# StarFive VisionFive 2 v1.3b register map
File version: 0.1
Registers are 32-bit, read-write, no defined reset value unless marked. A register's access mark holds for its fields unless they carry their own. Offsets are from the block's base; [hi:lo] are bit positions.

## starfive_jh7110_sys_pinctrl_0 (part 2 of 3) — From starfive,jh7110-sys-pinctrl, peripheral generator
Base 0x13040000
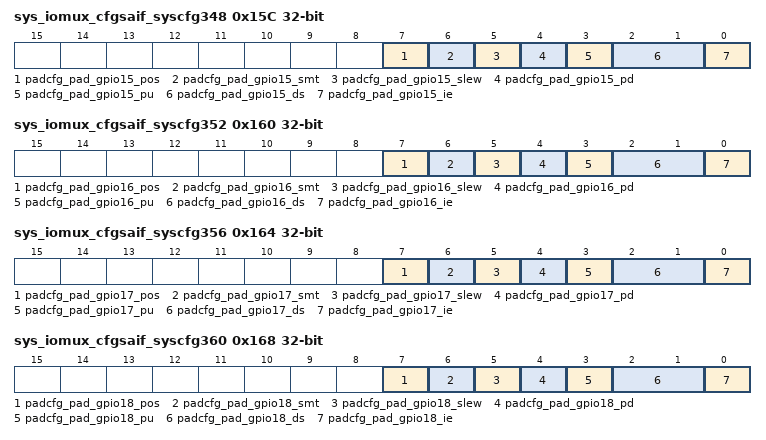
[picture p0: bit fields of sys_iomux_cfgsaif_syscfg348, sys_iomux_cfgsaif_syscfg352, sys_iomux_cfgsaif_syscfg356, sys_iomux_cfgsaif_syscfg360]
0x15C sys_iomux_cfgsaif_syscfg348
  [7] padcfg_pad_gpio15_pos — Power-on-Start (POS) enabler - 1: Enable active pull down for loss of core power, 0: Active pull-down capability disabled
  [6] padcfg_pad_gpio15_smt — Active high Schmitt (SMT) trigger selector - 0: No hysteresis, 1: Schmitt trigger ebabled
  [5] padcfg_pad_gpio15_slew — Slew Rate Control - 0: Slow (Half frequency), 1: Fast
  [4] padcfg_pad_gpio15_pd — Pull-Down (PD) settings - 1: Yes, 0: No
  [3] padcfg_pad_gpio15_pu — Pull-Up (PU) settings - 1: Yes, 0: No
  [2:1] padcfg_pad_gpio15_ds — Output Drive Strength (DS) - 00: The rated drive strength is 2 mA, 01: The rated drive strength is 4 mA, 10: The rated drive strength is 8 mA, 11: The rated drive strength is 12 mA
  [0] padcfg_pad_gpio15_ie — Input Enable (IE) Controller - 1: Enable the receiver, 0: Disable the receiver
0x160 sys_iomux_cfgsaif_syscfg352
  [7] padcfg_pad_gpio16_pos — Power-on-Start (POS) enabler - 1: Enable active pull down for loss of core power, 0: Active pull-down capability disabled
  [6] padcfg_pad_gpio16_smt — Active high Schmitt (SMT) trigger selector - 0: No hysteresis, 1: Schmitt trigger ebabled
  [5] padcfg_pad_gpio16_slew — Slew Rate Control - 0: Slow (Half frequency), 1: Fast
  [4] padcfg_pad_gpio16_pd — Pull-Down (PD) settings - 1: Yes, 0: No
  [3] padcfg_pad_gpio16_pu — Pull-Up (PU) settings - 1: Yes, 0: No
  [2:1] padcfg_pad_gpio16_ds — Output Drive Strength (DS) - 00: The rated drive strength is 2 mA, 01: The rated drive strength is 4 mA, 10: The rated drive strength is 8 mA, 11: The rated drive strength is 12 mA
  [0] padcfg_pad_gpio16_ie — Input Enable (IE) Controller - 1: Enable the receiver, 0: Disable the receiver
0x164 sys_iomux_cfgsaif_syscfg356
  [7] padcfg_pad_gpio17_pos — Power-on-Start (POS) enabler - 1: Enable active pull down for loss of core power, 0: Active pull-down capability disabled
  [6] padcfg_pad_gpio17_smt — Active high Schmitt (SMT) trigger selector - 0: No hysteresis, 1: Schmitt trigger ebabled
  [5] padcfg_pad_gpio17_slew — Slew Rate Control - 0: Slow (Half frequency), 1: Fast
  [4] padcfg_pad_gpio17_pd — Pull-Down (PD) settings - 1: Yes, 0: No
  [3] padcfg_pad_gpio17_pu — Pull-Up (PU) settings - 1: Yes, 0: No
  [2:1] padcfg_pad_gpio17_ds — Output Drive Strength (DS) - 00: The rated drive strength is 2 mA, 01: The rated drive strength is 4 mA, 10: The rated drive strength is 8 mA, 11: The rated drive strength is 12 mA
  [0] padcfg_pad_gpio17_ie — Input Enable (IE) Controller - 1: Enable the receiver, 0: Disable the receiver
0x168 sys_iomux_cfgsaif_syscfg360
  [7] padcfg_pad_gpio18_pos — Power-on-Start (POS) enabler - 1: Enable active pull down for loss of core power, 0: Active pull-down capability disabled
  [6] padcfg_pad_gpio18_smt — Active high Schmitt (SMT) trigger selector - 0: No hysteresis, 1: Schmitt trigger ebabled
  [5] padcfg_pad_gpio18_slew — Slew Rate Control - 0: Slow (Half frequency), 1: Fast
  [4] padcfg_pad_gpio18_pd — Pull-Down (PD) settings - 1: Yes, 0: No
  [3] padcfg_pad_gpio18_pu — Pull-Up (PU) settings - 1: Yes, 0: No
  [2:1] padcfg_pad_gpio18_ds — Output Drive Strength (DS) - 00: The rated drive strength is 2 mA, 01: The rated drive strength is 4 mA, 10: The rated drive strength is 8 mA, 11: The rated drive strength is 12 mA
  [0] padcfg_pad_gpio18_ie — Input Enable (IE) Controller - 1: Enable the receiver, 0: Disable the receiver
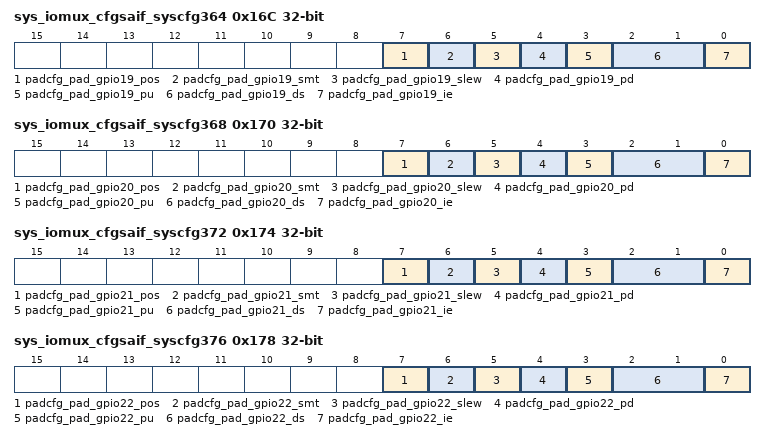
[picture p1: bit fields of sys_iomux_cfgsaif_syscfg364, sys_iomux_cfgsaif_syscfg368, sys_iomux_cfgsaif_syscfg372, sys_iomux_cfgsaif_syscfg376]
0x16C sys_iomux_cfgsaif_syscfg364
  [7] padcfg_pad_gpio19_pos — Power-on-Start (POS) enabler - 1: Enable active pull down for loss of core power, 0: Active pull-down capability disabled
  [6] padcfg_pad_gpio19_smt — Active high Schmitt (SMT) trigger selector - 0: No hysteresis, 1: Schmitt trigger ebabled
  [5] padcfg_pad_gpio19_slew — Slew Rate Control - 0: Slow (Half frequency), 1: Fast
  [4] padcfg_pad_gpio19_pd — Pull-Down (PD) settings - 1: Yes, 0: No
  [3] padcfg_pad_gpio19_pu — Pull-Up (PU) settings - 1: Yes, 0: No
  [2:1] padcfg_pad_gpio19_ds — Output Drive Strength (DS) - 00: The rated drive strength is 2 mA, 01: The rated drive strength is 4 mA, 10: The rated drive strength is 8 mA, 11: The rated drive strength is 12 mA
  [0] padcfg_pad_gpio19_ie — Input Enable (IE) Controller - 1: Enable the receiver, 0: Disable the receiver
0x170 sys_iomux_cfgsaif_syscfg368
  [7] padcfg_pad_gpio20_pos — Power-on-Start (POS) enabler - 1: Enable active pull down for loss of core power, 0: Active pull-down capability disabled
  [6] padcfg_pad_gpio20_smt — Active high Schmitt (SMT) trigger selector - 0: No hysteresis, 1: Schmitt trigger ebabled
  [5] padcfg_pad_gpio20_slew — Slew Rate Control - 0: Slow (Half frequency), 1: Fast
  [4] padcfg_pad_gpio20_pd — Pull-Down (PD) settings - 1: Yes, 0: No
  [3] padcfg_pad_gpio20_pu — Pull-Up (PU) settings - 1: Yes, 0: No
  [2:1] padcfg_pad_gpio20_ds — Output Drive Strength (DS) - 00: The rated drive strength is 2 mA, 01: The rated drive strength is 4 mA, 10: The rated drive strength is 8 mA, 11: The rated drive strength is 12 mA
  [0] padcfg_pad_gpio20_ie — Input Enable (IE) Controller - 1: Enable the receiver, 0: Disable the receiver
0x174 sys_iomux_cfgsaif_syscfg372
  [7] padcfg_pad_gpio21_pos — Power-on-Start (POS) enabler - 1: Enable active pull down for loss of core power, 0: Active pull-down capability disabled
  [6] padcfg_pad_gpio21_smt — Active high Schmitt (SMT) trigger selector - 0: No hysteresis, 1: Schmitt trigger ebabled
  [5] padcfg_pad_gpio21_slew — Slew Rate Control - 0: Slow (Half frequency), 1: Fast
  [4] padcfg_pad_gpio21_pd — Pull-Down (PD) settings - 1: Yes, 0: No
  [3] padcfg_pad_gpio21_pu — Pull-Up (PU) settings - 1: Yes, 0: No
  [2:1] padcfg_pad_gpio21_ds — Output Drive Strength (DS) - 00: The rated drive strength is 2 mA, 01: The rated drive strength is 4 mA, 10: The rated drive strength is 8 mA, 11: The rated drive strength is 12 mA
  [0] padcfg_pad_gpio21_ie — Input Enable (IE) Controller - 1: Enable the receiver, 0: Disable the receiver
0x178 sys_iomux_cfgsaif_syscfg376
  [7] padcfg_pad_gpio22_pos — Power-on-Start (POS) enabler - 1: Enable active pull down for loss of core power, 0: Active pull-down capability disabled
  [6] padcfg_pad_gpio22_smt — Active high Schmitt (SMT) trigger selector - 0: No hysteresis, 1: Schmitt trigger ebabled
  [5] padcfg_pad_gpio22_slew — Slew Rate Control - 0: Slow (Half frequency), 1: Fast
  [4] padcfg_pad_gpio22_pd — Pull-Down (PD) settings - 1: Yes, 0: No
  [3] padcfg_pad_gpio22_pu — Pull-Up (PU) settings - 1: Yes, 0: No
  [2:1] padcfg_pad_gpio22_ds — Output Drive Strength (DS) - 00: The rated drive strength is 2 mA, 01: The rated drive strength is 4 mA, 10: The rated drive strength is 8 mA, 11: The rated drive strength is 12 mA
  [0] padcfg_pad_gpio22_ie — Input Enable (IE) Controller - 1: Enable the receiver, 0: Disable the receiver
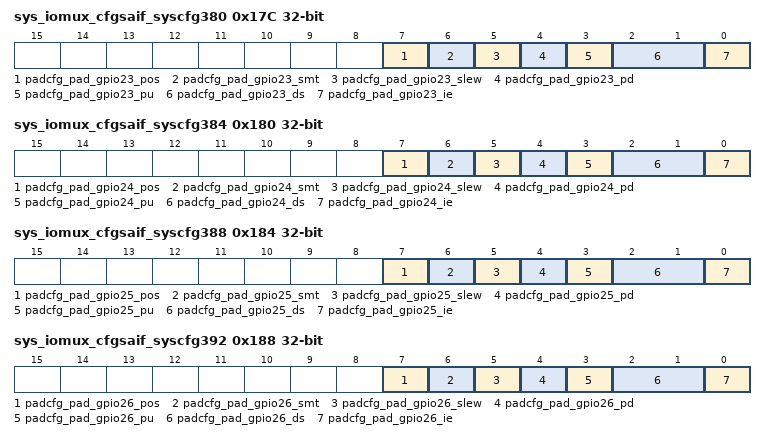
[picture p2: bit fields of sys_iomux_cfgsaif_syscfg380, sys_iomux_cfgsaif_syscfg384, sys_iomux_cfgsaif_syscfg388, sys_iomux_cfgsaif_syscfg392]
0x17C sys_iomux_cfgsaif_syscfg380
  [7] padcfg_pad_gpio23_pos — Power-on-Start (POS) enabler - 1: Enable active pull down for loss of core power, 0: Active pull-down capability disabled
  [6] padcfg_pad_gpio23_smt — Active high Schmitt (SMT) trigger selector - 0: No hysteresis, 1: Schmitt trigger ebabled
  [5] padcfg_pad_gpio23_slew — Slew Rate Control - 0: Slow (Half frequency), 1: Fast
  [4] padcfg_pad_gpio23_pd — Pull-Down (PD) settings - 1: Yes, 0: No
  [3] padcfg_pad_gpio23_pu — Pull-Up (PU) settings - 1: Yes, 0: No
  [2:1] padcfg_pad_gpio23_ds — Output Drive Strength (DS) - 00: The rated drive strength is 2 mA, 01: The rated drive strength is 4 mA, 10: The rated drive strength is 8 mA, 11: The rated drive strength is 12 mA
  [0] padcfg_pad_gpio23_ie — Input Enable (IE) Controller - 1: Enable the receiver, 0: Disable the receiver
0x180 sys_iomux_cfgsaif_syscfg384
  [7] padcfg_pad_gpio24_pos — Power-on-Start (POS) enabler - 1: Enable active pull down for loss of core power, 0: Active pull-down capability disabled
  [6] padcfg_pad_gpio24_smt — Active high Schmitt (SMT) trigger selector - 0: No hysteresis, 1: Schmitt trigger ebabled
  [5] padcfg_pad_gpio24_slew — Slew Rate Control - 0: Slow (Half frequency), 1: Fast
  [4] padcfg_pad_gpio24_pd — Pull-Down (PD) settings - 1: Yes, 0: No
  [3] padcfg_pad_gpio24_pu — Pull-Up (PU) settings - 1: Yes, 0: No
  [2:1] padcfg_pad_gpio24_ds — Output Drive Strength (DS) - 00: The rated drive strength is 2 mA, 01: The rated drive strength is 4 mA, 10: The rated drive strength is 8 mA, 11: The rated drive strength is 12 mA
  [0] padcfg_pad_gpio24_ie — Input Enable (IE) Controller - 1: Enable the receiver, 0: Disable the receiver
0x184 sys_iomux_cfgsaif_syscfg388
  [7] padcfg_pad_gpio25_pos — Power-on-Start (POS) enabler - 1: Enable active pull down for loss of core power, 0: Active pull-down capability disabled
  [6] padcfg_pad_gpio25_smt — Active high Schmitt (SMT) trigger selector - 0: No hysteresis, 1: Schmitt trigger ebabled
  [5] padcfg_pad_gpio25_slew — Slew Rate Control - 0: Slow (Half frequency), 1: Fast
  [4] padcfg_pad_gpio25_pd — Pull-Down (PD) settings - 1: Yes, 0: No
  [3] padcfg_pad_gpio25_pu — Pull-Up (PU) settings - 1: Yes, 0: No
  [2:1] padcfg_pad_gpio25_ds — Output Drive Strength (DS) - 00: The rated drive strength is 2 mA, 01: The rated drive strength is 4 mA, 10: The rated drive strength is 8 mA, 11: The rated drive strength is 12 mA
  [0] padcfg_pad_gpio25_ie — Input Enable (IE) Controller - 1: Enable the receiver, 0: Disable the receiver
0x188 sys_iomux_cfgsaif_syscfg392
  [7] padcfg_pad_gpio26_pos — Power-on-Start (POS) enabler - 1: Enable active pull down for loss of core power, 0: Active pull-down capability disabled
  [6] padcfg_pad_gpio26_smt — Active high Schmitt (SMT) trigger selector - 0: No hysteresis, 1: Schmitt trigger ebabled
  [5] padcfg_pad_gpio26_slew — Slew Rate Control - 0: Slow (Half frequency), 1: Fast
  [4] padcfg_pad_gpio26_pd — Pull-Down (PD) settings - 1: Yes, 0: No
  [3] padcfg_pad_gpio26_pu — Pull-Up (PU) settings - 1: Yes, 0: No
  [2:1] padcfg_pad_gpio26_ds — Output Drive Strength (DS) - 00: The rated drive strength is 2 mA, 01: The rated drive strength is 4 mA, 10: The rated drive strength is 8 mA, 11: The rated drive strength is 12 mA
  [0] padcfg_pad_gpio26_ie — Input Enable (IE) Controller - 1: Enable the receiver, 0: Disable the receiver
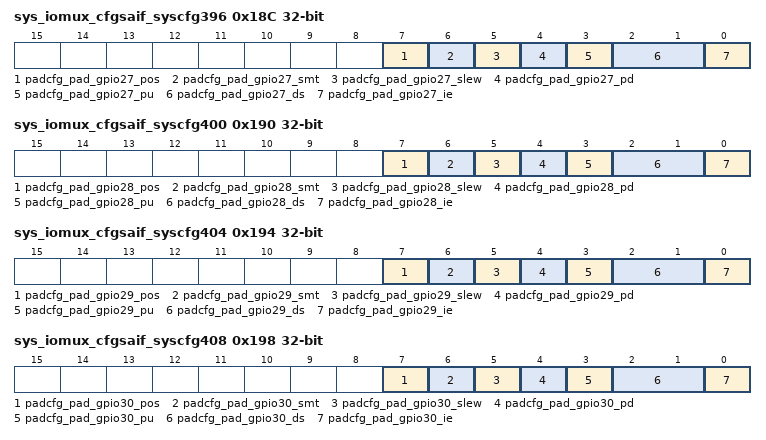
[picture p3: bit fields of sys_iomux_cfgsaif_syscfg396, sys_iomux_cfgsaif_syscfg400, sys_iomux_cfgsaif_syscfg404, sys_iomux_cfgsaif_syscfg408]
0x18C sys_iomux_cfgsaif_syscfg396
  [7] padcfg_pad_gpio27_pos — Power-on-Start (POS) enabler - 1: Enable active pull down for loss of core power, 0: Active pull-down capability disabled
  [6] padcfg_pad_gpio27_smt — Active high Schmitt (SMT) trigger selector - 0: No hysteresis, 1: Schmitt trigger ebabled
  [5] padcfg_pad_gpio27_slew — Slew Rate Control - 0: Slow (Half frequency), 1: Fast
  [4] padcfg_pad_gpio27_pd — Pull-Down (PD) settings - 1: Yes, 0: No
  [3] padcfg_pad_gpio27_pu — Pull-Up (PU) settings - 1: Yes, 0: No
  [2:1] padcfg_pad_gpio27_ds — Output Drive Strength (DS) - 00: The rated drive strength is 2 mA, 01: The rated drive strength is 4 mA, 10: The rated drive strength is 8 mA, 11: The rated drive strength is 12 mA
  [0] padcfg_pad_gpio27_ie — Input Enable (IE) Controller - 1: Enable the receiver, 0: Disable the receiver
0x190 sys_iomux_cfgsaif_syscfg400
  [7] padcfg_pad_gpio28_pos — Power-on-Start (POS) enabler - 1: Enable active pull down for loss of core power, 0: Active pull-down capability disabled
  [6] padcfg_pad_gpio28_smt — Active high Schmitt (SMT) trigger selector - 0: No hysteresis, 1: Schmitt trigger ebabled
  [5] padcfg_pad_gpio28_slew — Slew Rate Control - 0: Slow (Half frequency), 1: Fast
  [4] padcfg_pad_gpio28_pd — Pull-Down (PD) settings - 1: Yes, 0: No
  [3] padcfg_pad_gpio28_pu — Pull-Up (PU) settings - 1: Yes, 0: No
  [2:1] padcfg_pad_gpio28_ds — Output Drive Strength (DS) - 00: The rated drive strength is 2 mA, 01: The rated drive strength is 4 mA, 10: The rated drive strength is 8 mA, 11: The rated drive strength is 12 mA
  [0] padcfg_pad_gpio28_ie — Input Enable (IE) Controller - 1: Enable the receiver, 0: Disable the receiver
0x194 sys_iomux_cfgsaif_syscfg404
  [7] padcfg_pad_gpio29_pos — Power-on-Start (POS) enabler - 1: Enable active pull down for loss of core power, 0: Active pull-down capability disabled
  [6] padcfg_pad_gpio29_smt — Active high Schmitt (SMT) trigger selector - 0: No hysteresis, 1: Schmitt trigger ebabled
  [5] padcfg_pad_gpio29_slew — Slew Rate Control - 0: Slow (Half frequency), 1: Fast
  [4] padcfg_pad_gpio29_pd — Pull-Down (PD) settings - 1: Yes, 0: No
  [3] padcfg_pad_gpio29_pu — Pull-Up (PU) settings - 1: Yes, 0: No
  [2:1] padcfg_pad_gpio29_ds — Output Drive Strength (DS) - 00: The rated drive strength is 2 mA, 01: The rated drive strength is 4 mA, 10: The rated drive strength is 8 mA, 11: The rated drive strength is 12 mA
  [0] padcfg_pad_gpio29_ie — Input Enable (IE) Controller - 1: Enable the receiver, 0: Disable the receiver
0x198 sys_iomux_cfgsaif_syscfg408
  [7] padcfg_pad_gpio30_pos — Power-on-Start (POS) enabler - 1: Enable active pull down for loss of core power, 0: Active pull-down capability disabled
  [6] padcfg_pad_gpio30_smt — Active high Schmitt (SMT) trigger selector - 0: No hysteresis, 1: Schmitt trigger ebabled
  [5] padcfg_pad_gpio30_slew — Slew Rate Control - 0: Slow (Half frequency), 1: Fast
  [4] padcfg_pad_gpio30_pd — Pull-Down (PD) settings - 1: Yes, 0: No
  [3] padcfg_pad_gpio30_pu — Pull-Up (PU) settings - 1: Yes, 0: No
  [2:1] padcfg_pad_gpio30_ds — Output Drive Strength (DS) - 00: The rated drive strength is 2 mA, 01: The rated drive strength is 4 mA, 10: The rated drive strength is 8 mA, 11: The rated drive strength is 12 mA
  [0] padcfg_pad_gpio30_ie — Input Enable (IE) Controller - 1: Enable the receiver, 0: Disable the receiver
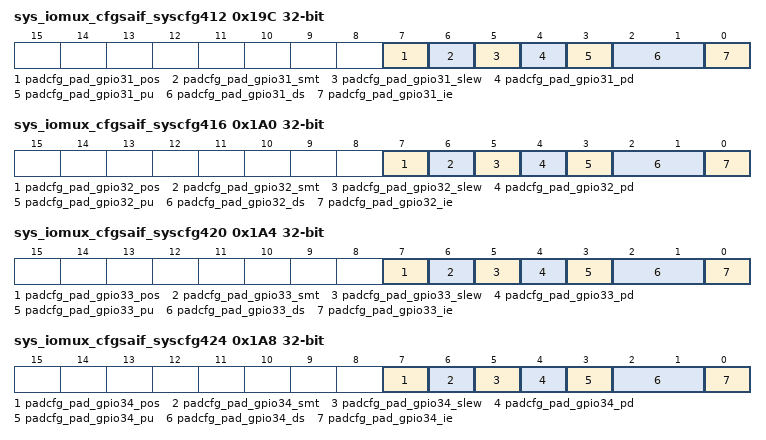
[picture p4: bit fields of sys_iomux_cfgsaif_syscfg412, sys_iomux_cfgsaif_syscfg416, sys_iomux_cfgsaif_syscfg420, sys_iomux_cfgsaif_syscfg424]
0x19C sys_iomux_cfgsaif_syscfg412
  [7] padcfg_pad_gpio31_pos — Power-on-Start (POS) enabler - 1: Enable active pull down for loss of core power, 0: Active pull-down capability disabled
  [6] padcfg_pad_gpio31_smt — Active high Schmitt (SMT) trigger selector - 0: No hysteresis, 1: Schmitt trigger ebabled
  [5] padcfg_pad_gpio31_slew — Slew Rate Control - 0: Slow (Half frequency), 1: Fast
  [4] padcfg_pad_gpio31_pd — Pull-Down (PD) settings - 1: Yes, 0: No
  [3] padcfg_pad_gpio31_pu — Pull-Up (PU) settings - 1: Yes, 0: No
  [2:1] padcfg_pad_gpio31_ds — Output Drive Strength (DS) - 00: The rated drive strength is 2 mA, 01: The rated drive strength is 4 mA, 10: The rated drive strength is 8 mA, 11: The rated drive strength is 12 mA
  [0] padcfg_pad_gpio31_ie — Input Enable (IE) Controller - 1: Enable the receiver, 0: Disable the receiver
0x1A0 sys_iomux_cfgsaif_syscfg416
  [7] padcfg_pad_gpio32_pos — Power-on-Start (POS) enabler - 1: Enable active pull down for loss of core power, 0: Active pull-down capability disabled
  [6] padcfg_pad_gpio32_smt — Active high Schmitt (SMT) trigger selector - 0: No hysteresis, 1: Schmitt trigger ebabled
  [5] padcfg_pad_gpio32_slew — Slew Rate Control - 0: Slow (Half frequency), 1: Fast
  [4] padcfg_pad_gpio32_pd — Pull-Down (PD) settings - 1: Yes, 0: No
  [3] padcfg_pad_gpio32_pu — Pull-Up (PU) settings - 1: Yes, 0: No
  [2:1] padcfg_pad_gpio32_ds — Output Drive Strength (DS) - 00: The rated drive strength is 2 mA, 01: The rated drive strength is 4 mA, 10: The rated drive strength is 8 mA, 11: The rated drive strength is 12 mA
  [0] padcfg_pad_gpio32_ie — Input Enable (IE) Controller - 1: Enable the receiver, 0: Disable the receiver
0x1A4 sys_iomux_cfgsaif_syscfg420
  [7] padcfg_pad_gpio33_pos — Power-on-Start (POS) enabler - 1: Enable active pull down for loss of core power, 0: Active pull-down capability disabled
  [6] padcfg_pad_gpio33_smt — Active high Schmitt (SMT) trigger selector - 0: No hysteresis, 1: Schmitt trigger ebabled
  [5] padcfg_pad_gpio33_slew — Slew Rate Control - 0: Slow (Half frequency), 1: Fast
  [4] padcfg_pad_gpio33_pd — Pull-Down (PD) settings - 1: Yes, 0: No
  [3] padcfg_pad_gpio33_pu — Pull-Up (PU) settings - 1: Yes, 0: No
  [2:1] padcfg_pad_gpio33_ds — Output Drive Strength (DS) - 00: The rated drive strength is 2 mA, 01: The rated drive strength is 4 mA, 10: The rated drive strength is 8 mA, 11: The rated drive strength is 12 mA
  [0] padcfg_pad_gpio33_ie — Input Enable (IE) Controller - 1: Enable the receiver, 0: Disable the receiver
0x1A8 sys_iomux_cfgsaif_syscfg424
  [7] padcfg_pad_gpio34_pos — Power-on-Start (POS) enabler - 1: Enable active pull down for loss of core power, 0: Active pull-down capability disabled
  [6] padcfg_pad_gpio34_smt — Active high Schmitt (SMT) trigger selector - 0: No hysteresis, 1: Schmitt trigger ebabled
  [5] padcfg_pad_gpio34_slew — Slew Rate Control - 0: Slow (Half frequency), 1: Fast
  [4] padcfg_pad_gpio34_pd — Pull-Down (PD) settings - 1: Yes, 0: No
  [3] padcfg_pad_gpio34_pu — Pull-Up (PU) settings - 1: Yes, 0: No
  [2:1] padcfg_pad_gpio34_ds — Output Drive Strength (DS) - 00: The rated drive strength is 2 mA, 01: The rated drive strength is 4 mA, 10: The rated drive strength is 8 mA, 11: The rated drive strength is 12 mA
  [0] padcfg_pad_gpio34_ie — Input Enable (IE) Controller - 1: Enable the receiver, 0: Disable the receiver
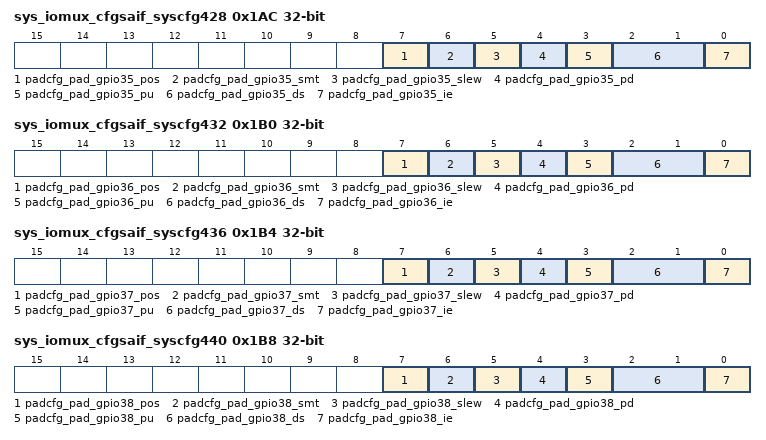
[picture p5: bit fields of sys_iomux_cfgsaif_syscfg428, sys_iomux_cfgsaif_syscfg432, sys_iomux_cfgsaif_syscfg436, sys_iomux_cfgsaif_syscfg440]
0x1AC sys_iomux_cfgsaif_syscfg428
  [7] padcfg_pad_gpio35_pos — Power-on-Start (POS) enabler - 1: Enable active pull down for loss of core power, 0: Active pull-down capability disabled
  [6] padcfg_pad_gpio35_smt — Active high Schmitt (SMT) trigger selector - 0: No hysteresis, 1: Schmitt trigger ebabled
  [5] padcfg_pad_gpio35_slew — Slew Rate Control - 0: Slow (Half frequency), 1: Fast
  [4] padcfg_pad_gpio35_pd — Pull-Down (PD) settings - 1: Yes, 0: No
  [3] padcfg_pad_gpio35_pu — Pull-Up (PU) settings - 1: Yes, 0: No
  [2:1] padcfg_pad_gpio35_ds — Output Drive Strength (DS) - 00: The rated drive strength is 2 mA, 01: The rated drive strength is 4 mA, 10: The rated drive strength is 8 mA, 11: The rated drive strength is 12 mA
  [0] padcfg_pad_gpio35_ie — Input Enable (IE) Controller - 1: Enable the receiver, 0: Disable the receiver
0x1B0 sys_iomux_cfgsaif_syscfg432
  [7] padcfg_pad_gpio36_pos — Power-on-Start (POS) enabler - 1: Enable active pull down for loss of core power, 0: Active pull-down capability disabled
  [6] padcfg_pad_gpio36_smt — Active high Schmitt (SMT) trigger selector - 0: No hysteresis, 1: Schmitt trigger ebabled
  [5] padcfg_pad_gpio36_slew — Slew Rate Control - 0: Slow (Half frequency), 1: Fast
  [4] padcfg_pad_gpio36_pd — Pull-Down (PD) settings - 1: Yes, 0: No
  [3] padcfg_pad_gpio36_pu — Pull-Up (PU) settings - 1: Yes, 0: No
  [2:1] padcfg_pad_gpio36_ds — Output Drive Strength (DS) - 00: The rated drive strength is 2 mA, 01: The rated drive strength is 4 mA, 10: The rated drive strength is 8 mA, 11: The rated drive strength is 12 mA
  [0] padcfg_pad_gpio36_ie — Input Enable (IE) Controller - 1: Enable the receiver, 0: Disable the receiver
0x1B4 sys_iomux_cfgsaif_syscfg436
  [7] padcfg_pad_gpio37_pos — Power-on-Start (POS) enabler - 1: Enable active pull down for loss of core power, 0: Active pull-down capability disabled
  [6] padcfg_pad_gpio37_smt — Active high Schmitt (SMT) trigger selector - 0: No hysteresis, 1: Schmitt trigger ebabled
  [5] padcfg_pad_gpio37_slew — Slew Rate Control - 0: Slow (Half frequency), 1: Fast
  [4] padcfg_pad_gpio37_pd — Pull-Down (PD) settings - 1: Yes, 0: No
  [3] padcfg_pad_gpio37_pu — Pull-Up (PU) settings - 1: Yes, 0: No
  [2:1] padcfg_pad_gpio37_ds — Output Drive Strength (DS) - 00: The rated drive strength is 2 mA, 01: The rated drive strength is 4 mA, 10: The rated drive strength is 8 mA, 11: The rated drive strength is 12 mA
  [0] padcfg_pad_gpio37_ie — Input Enable (IE) Controller - 1: Enable the receiver, 0: Disable the receiver
0x1B8 sys_iomux_cfgsaif_syscfg440
  [7] padcfg_pad_gpio38_pos — Power-on-Start (POS) enabler - 1: Enable active pull down for loss of core power, 0: Active pull-down capability disabled
  [6] padcfg_pad_gpio38_smt — Active high Schmitt (SMT) trigger selector - 0: No hysteresis, 1: Schmitt trigger ebabled
  [5] padcfg_pad_gpio38_slew — Slew Rate Control - 0: Slow (Half frequency), 1: Fast
  [4] padcfg_pad_gpio38_pd — Pull-Down (PD) settings - 1: Yes, 0: No
  [3] padcfg_pad_gpio38_pu — Pull-Up (PU) settings - 1: Yes, 0: No
  [2:1] padcfg_pad_gpio38_ds — Output Drive Strength (DS) - 00: The rated drive strength is 2 mA, 01: The rated drive strength is 4 mA, 10: The rated drive strength is 8 mA, 11: The rated drive strength is 12 mA
  [0] padcfg_pad_gpio38_ie — Input Enable (IE) Controller - 1: Enable the receiver, 0: Disable the receiver
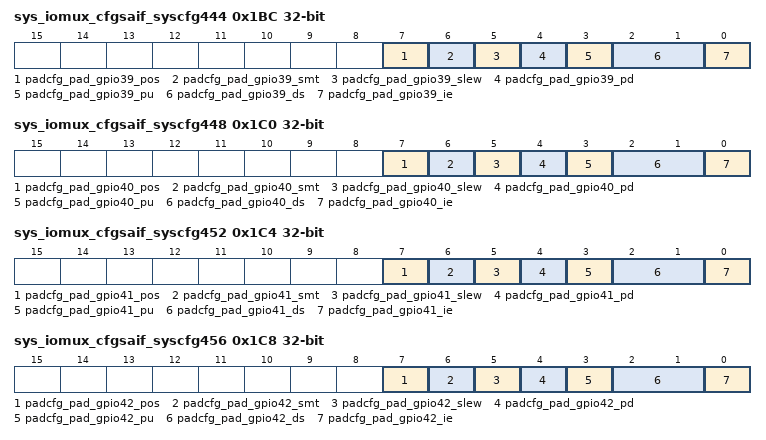
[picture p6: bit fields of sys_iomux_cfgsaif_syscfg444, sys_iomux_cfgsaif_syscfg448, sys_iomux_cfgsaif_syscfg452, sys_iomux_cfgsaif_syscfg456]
0x1BC sys_iomux_cfgsaif_syscfg444
  [7] padcfg_pad_gpio39_pos — Power-on-Start (POS) enabler - 1: Enable active pull down for loss of core power, 0: Active pull-down capability disabled
  [6] padcfg_pad_gpio39_smt — Active high Schmitt (SMT) trigger selector - 0: No hysteresis, 1: Schmitt trigger ebabled
  [5] padcfg_pad_gpio39_slew — Slew Rate Control - 0: Slow (Half frequency), 1: Fast
  [4] padcfg_pad_gpio39_pd — Pull-Down (PD) settings - 1: Yes, 0: No
  [3] padcfg_pad_gpio39_pu — Pull-Up (PU) settings - 1: Yes, 0: No
  [2:1] padcfg_pad_gpio39_ds — Output Drive Strength (DS) - 00: The rated drive strength is 2 mA, 01: The rated drive strength is 4 mA, 10: The rated drive strength is 8 mA, 11: The rated drive strength is 12 mA
  [0] padcfg_pad_gpio39_ie — Input Enable (IE) Controller - 1: Enable the receiver, 0: Disable the receiver
0x1C0 sys_iomux_cfgsaif_syscfg448
  [7] padcfg_pad_gpio40_pos — Power-on-Start (POS) enabler - 1: Enable active pull down for loss of core power, 0: Active pull-down capability disabled
  [6] padcfg_pad_gpio40_smt — Active high Schmitt (SMT) trigger selector - 0: No hysteresis, 1: Schmitt trigger ebabled
  [5] padcfg_pad_gpio40_slew — Slew Rate Control - 0: Slow (Half frequency), 1: Fast
  [4] padcfg_pad_gpio40_pd — Pull-Down (PD) settings - 1: Yes, 0: No
  [3] padcfg_pad_gpio40_pu — Pull-Up (PU) settings - 1: Yes, 0: No
  [2:1] padcfg_pad_gpio40_ds — Output Drive Strength (DS) - 00: The rated drive strength is 2 mA, 01: The rated drive strength is 4 mA, 10: The rated drive strength is 8 mA, 11: The rated drive strength is 12 mA
  [0] padcfg_pad_gpio40_ie — Input Enable (IE) Controller - 1: Enable the receiver, 0: Disable the receiver
0x1C4 sys_iomux_cfgsaif_syscfg452
  [7] padcfg_pad_gpio41_pos — Power-on-Start (POS) enabler - 1: Enable active pull down for loss of core power, 0: Active pull-down capability disabled
  [6] padcfg_pad_gpio41_smt — Active high Schmitt (SMT) trigger selector - 0: No hysteresis, 1: Schmitt trigger ebabled
  [5] padcfg_pad_gpio41_slew — Slew Rate Control - 0: Slow (Half frequency), 1: Fast
  [4] padcfg_pad_gpio41_pd — Pull-Down (PD) settings - 1: Yes, 0: No
  [3] padcfg_pad_gpio41_pu — Pull-Up (PU) settings - 1: Yes, 0: No
  [2:1] padcfg_pad_gpio41_ds — Output Drive Strength (DS) - 00: The rated drive strength is 2 mA, 01: The rated drive strength is 4 mA, 10: The rated drive strength is 8 mA, 11: The rated drive strength is 12 mA
  [0] padcfg_pad_gpio41_ie — Input Enable (IE) Controller - 1: Enable the receiver, 0: Disable the receiver
0x1C8 sys_iomux_cfgsaif_syscfg456
  [7] padcfg_pad_gpio42_pos — Power-on-Start (POS) enabler - 1: Enable active pull down for loss of core power, 0: Active pull-down capability disabled
  [6] padcfg_pad_gpio42_smt — Active high Schmitt (SMT) trigger selector - 0: No hysteresis, 1: Schmitt trigger ebabled
  [5] padcfg_pad_gpio42_slew — Slew Rate Control - 0: Slow (Half frequency), 1: Fast
  [4] padcfg_pad_gpio42_pd — Pull-Down (PD) settings - 1: Yes, 0: No
  [3] padcfg_pad_gpio42_pu — Pull-Up (PU) settings - 1: Yes, 0: No
  [2:1] padcfg_pad_gpio42_ds — Output Drive Strength (DS) - 00: The rated drive strength is 2 mA, 01: The rated drive strength is 4 mA, 10: The rated drive strength is 8 mA, 11: The rated drive strength is 12 mA
  [0] padcfg_pad_gpio42_ie — Input Enable (IE) Controller - 1: Enable the receiver, 0: Disable the receiver
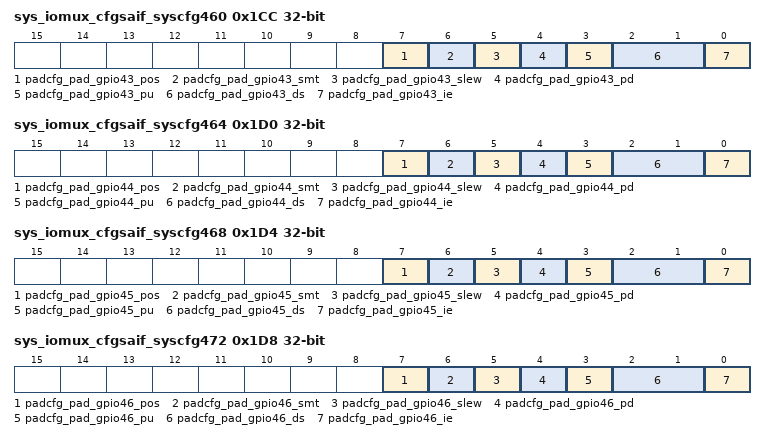
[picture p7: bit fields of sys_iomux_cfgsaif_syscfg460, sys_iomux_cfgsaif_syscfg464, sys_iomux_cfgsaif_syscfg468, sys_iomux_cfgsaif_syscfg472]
0x1CC sys_iomux_cfgsaif_syscfg460
  [7] padcfg_pad_gpio43_pos — Power-on-Start (POS) enabler - 1: Enable active pull down for loss of core power, 0: Active pull-down capability disabled
  [6] padcfg_pad_gpio43_smt — Active high Schmitt (SMT) trigger selector - 0: No hysteresis, 1: Schmitt trigger ebabled
  [5] padcfg_pad_gpio43_slew — Slew Rate Control - 0: Slow (Half frequency), 1: Fast
  [4] padcfg_pad_gpio43_pd — Pull-Down (PD) settings - 1: Yes, 0: No
  [3] padcfg_pad_gpio43_pu — Pull-Up (PU) settings - 1: Yes, 0: No
  [2:1] padcfg_pad_gpio43_ds — Output Drive Strength (DS) - 00: The rated drive strength is 2 mA, 01: The rated drive strength is 4 mA, 10: The rated drive strength is 8 mA, 11: The rated drive strength is 12 mA
  [0] padcfg_pad_gpio43_ie — Input Enable (IE) Controller - 1: Enable the receiver, 0: Disable the receiver
0x1D0 sys_iomux_cfgsaif_syscfg464
  [7] padcfg_pad_gpio44_pos — Power-on-Start (POS) enabler - 1: Enable active pull down for loss of core power, 0: Active pull-down capability disabled
  [6] padcfg_pad_gpio44_smt — Active high Schmitt (SMT) trigger selector - 0: No hysteresis, 1: Schmitt trigger ebabled
  [5] padcfg_pad_gpio44_slew — Slew Rate Control - 0: Slow (Half frequency), 1: Fast
  [4] padcfg_pad_gpio44_pd — Pull-Down (PD) settings - 1: Yes, 0: No
  [3] padcfg_pad_gpio44_pu — Pull-Up (PU) settings - 1: Yes, 0: No
  [2:1] padcfg_pad_gpio44_ds — Output Drive Strength (DS) - 00: The rated drive strength is 2 mA, 01: The rated drive strength is 4 mA, 10: The rated drive strength is 8 mA, 11: The rated drive strength is 12 mA
  [0] padcfg_pad_gpio44_ie — Input Enable (IE) Controller - 1: Enable the receiver, 0: Disable the receiver
0x1D4 sys_iomux_cfgsaif_syscfg468
  [7] padcfg_pad_gpio45_pos — Power-on-Start (POS) enabler - 1: Enable active pull down for loss of core power, 0: Active pull-down capability disabled
  [6] padcfg_pad_gpio45_smt — Active high Schmitt (SMT) trigger selector - 0: No hysteresis, 1: Schmitt trigger ebabled
  [5] padcfg_pad_gpio45_slew — Slew Rate Control - 0: Slow (Half frequency), 1: Fast
  [4] padcfg_pad_gpio45_pd — Pull-Down (PD) settings - 1: Yes, 0: No
  [3] padcfg_pad_gpio45_pu — Pull-Up (PU) settings - 1: Yes, 0: No
  [2:1] padcfg_pad_gpio45_ds — Output Drive Strength (DS) - 00: The rated drive strength is 2 mA, 01: The rated drive strength is 4 mA, 10: The rated drive strength is 8 mA, 11: The rated drive strength is 12 mA
  [0] padcfg_pad_gpio45_ie — Input Enable (IE) Controller - 1: Enable the receiver, 0: Disable the receiver
0x1D8 sys_iomux_cfgsaif_syscfg472
  [7] padcfg_pad_gpio46_pos — Power-on-Start (POS) enabler - 1: Enable active pull down for loss of core power, 0: Active pull-down capability disabled
  [6] padcfg_pad_gpio46_smt — Active high Schmitt (SMT) trigger selector - 0: No hysteresis, 1: Schmitt trigger ebabled
  [5] padcfg_pad_gpio46_slew — Slew Rate Control - 0: Slow (Half frequency), 1: Fast
  [4] padcfg_pad_gpio46_pd — Pull-Down (PD) settings - 1: Yes, 0: No
  [3] padcfg_pad_gpio46_pu — Pull-Up (PU) settings - 1: Yes, 0: No
  [2:1] padcfg_pad_gpio46_ds — Output Drive Strength (DS) - 00: The rated drive strength is 2 mA, 01: The rated drive strength is 4 mA, 10: The rated drive strength is 8 mA, 11: The rated drive strength is 12 mA
  [0] padcfg_pad_gpio46_ie — Input Enable (IE) Controller - 1: Enable the receiver, 0: Disable the receiver
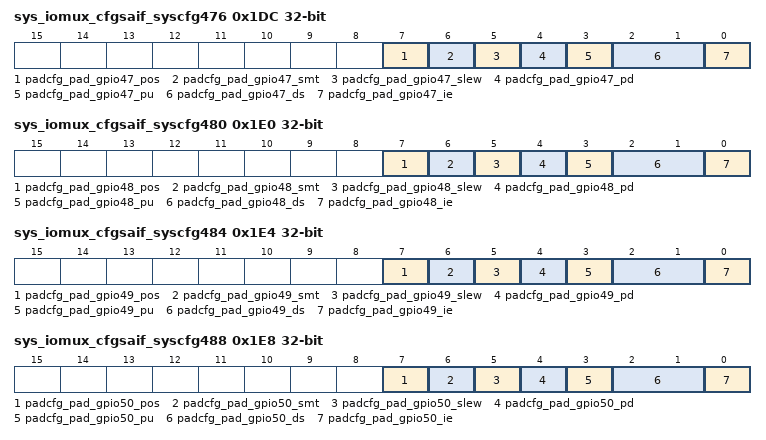
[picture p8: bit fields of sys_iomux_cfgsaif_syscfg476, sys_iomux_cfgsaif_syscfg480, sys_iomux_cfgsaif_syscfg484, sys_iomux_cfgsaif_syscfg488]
0x1DC sys_iomux_cfgsaif_syscfg476
  [7] padcfg_pad_gpio47_pos — Power-on-Start (POS) enabler - 1: Enable active pull down for loss of core power, 0: Active pull-down capability disabled
  [6] padcfg_pad_gpio47_smt — Active high Schmitt (SMT) trigger selector - 0: No hysteresis, 1: Schmitt trigger ebabled
  [5] padcfg_pad_gpio47_slew — Slew Rate Control - 0: Slow (Half frequency), 1: Fast
  [4] padcfg_pad_gpio47_pd — Pull-Down (PD) settings - 1: Yes, 0: No
  [3] padcfg_pad_gpio47_pu — Pull-Up (PU) settings - 1: Yes, 0: No
  [2:1] padcfg_pad_gpio47_ds — Output Drive Strength (DS) - 00: The rated drive strength is 2 mA, 01: The rated drive strength is 4 mA, 10: The rated drive strength is 8 mA, 11: The rated drive strength is 12 mA
  [0] padcfg_pad_gpio47_ie — Input Enable (IE) Controller - 1: Enable the receiver, 0: Disable the receiver
0x1E0 sys_iomux_cfgsaif_syscfg480
  [7] padcfg_pad_gpio48_pos — Power-on-Start (POS) enabler - 1: Enable active pull down for loss of core power, 0: Active pull-down capability disabled
  [6] padcfg_pad_gpio48_smt — Active high Schmitt (SMT) trigger selector - 0: No hysteresis, 1: Schmitt trigger ebabled
  [5] padcfg_pad_gpio48_slew — Slew Rate Control - 0: Slow (Half frequency), 1: Fast
  [4] padcfg_pad_gpio48_pd — Pull-Down (PD) settings - 1: Yes, 0: No
  [3] padcfg_pad_gpio48_pu — Pull-Up (PU) settings - 1: Yes, 0: No
  [2:1] padcfg_pad_gpio48_ds — Output Drive Strength (DS) - 00: The rated drive strength is 2 mA, 01: The rated drive strength is 4 mA, 10: The rated drive strength is 8 mA, 11: The rated drive strength is 12 mA
  [0] padcfg_pad_gpio48_ie — Input Enable (IE) Controller - 1: Enable the receiver, 0: Disable the receiver
0x1E4 sys_iomux_cfgsaif_syscfg484
  [7] padcfg_pad_gpio49_pos — Power-on-Start (POS) enabler - 1: Enable active pull down for loss of core power, 0: Active pull-down capability disabled
  [6] padcfg_pad_gpio49_smt — Active high Schmitt (SMT) trigger selector - 0: No hysteresis, 1: Schmitt trigger ebabled
  [5] padcfg_pad_gpio49_slew — Slew Rate Control - 0: Slow (Half frequency), 1: Fast
  [4] padcfg_pad_gpio49_pd — Pull-Down (PD) settings - 1: Yes, 0: No
  [3] padcfg_pad_gpio49_pu — Pull-Up (PU) settings - 1: Yes, 0: No
  [2:1] padcfg_pad_gpio49_ds — Output Drive Strength (DS) - 00: The rated drive strength is 2 mA, 01: The rated drive strength is 4 mA, 10: The rated drive strength is 8 mA, 11: The rated drive strength is 12 mA
  [0] padcfg_pad_gpio49_ie — Input Enable (IE) Controller - 1: Enable the receiver, 0: Disable the receiver
0x1E8 sys_iomux_cfgsaif_syscfg488
  [7] padcfg_pad_gpio50_pos — Power-on-Start (POS) enabler - 1: Enable active pull down for loss of core power, 0: Active pull-down capability disabled
  [6] padcfg_pad_gpio50_smt — Active high Schmitt (SMT) trigger selector - 0: No hysteresis, 1: Schmitt trigger ebabled
  [5] padcfg_pad_gpio50_slew — Slew Rate Control - 0: Slow (Half frequency), 1: Fast
  [4] padcfg_pad_gpio50_pd — Pull-Down (PD) settings - 1: Yes, 0: No
  [3] padcfg_pad_gpio50_pu — Pull-Up (PU) settings - 1: Yes, 0: No
  [2:1] padcfg_pad_gpio50_ds — Output Drive Strength (DS) - 00: The rated drive strength is 2 mA, 01: The rated drive strength is 4 mA, 10: The rated drive strength is 8 mA, 11: The rated drive strength is 12 mA
  [0] padcfg_pad_gpio50_ie — Input Enable (IE) Controller - 1: Enable the receiver, 0: Disable the receiver
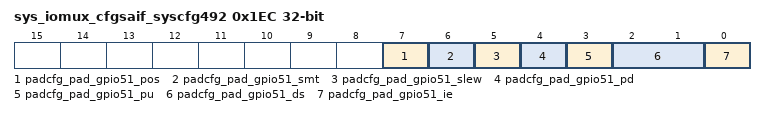
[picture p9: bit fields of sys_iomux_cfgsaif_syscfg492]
0x1EC sys_iomux_cfgsaif_syscfg492
  [7] padcfg_pad_gpio51_pos — Power-on-Start (POS) enabler - 1: Enable active pull down for loss of core power, 0: Active pull-down capability disabled
  [6] padcfg_pad_gpio51_smt — Active high Schmitt (SMT) trigger selector - 0: No hysteresis, 1: Schmitt trigger ebabled
  [5] padcfg_pad_gpio51_slew — Slew Rate Control - 0: Slow (Half frequency), 1: Fast
  [4] padcfg_pad_gpio51_pd — Pull-Down (PD) settings - 1: Yes, 0: No
  [3] padcfg_pad_gpio51_pu — Pull-Up (PU) settings - 1: Yes, 0: No
  [2:1] padcfg_pad_gpio51_ds — Output Drive Strength (DS) - 00: The rated drive strength is 2 mA, 01: The rated drive strength is 4 mA, 10: The rated drive strength is 8 mA, 11: The rated drive strength is 12 mA
  [0] padcfg_pad_gpio51_ie — Input Enable (IE) Controller - 1: Enable the receiver, 0: Disable the receiver
